# MISC_ANALOG_CTRL register map
Vendor: Texas Instruments
Peripheral module from a debugger description file (folder ucd3138064A).
Registers are 32-bit, access not given, no defined reset value unless marked. A register's access mark holds for its fields unless they carry their own. Offsets are as the file gives them; lines under a group give offsets from that group; [hi:lo] are bit positions; {n}, {i} and the like mark numbered series; 'fields as' and 'values as' point back to an identical list; <NAME> marks a mode.

## MISCANALOG
0x10 PKGID
  [1:0] PKG_ID rw — Package ID
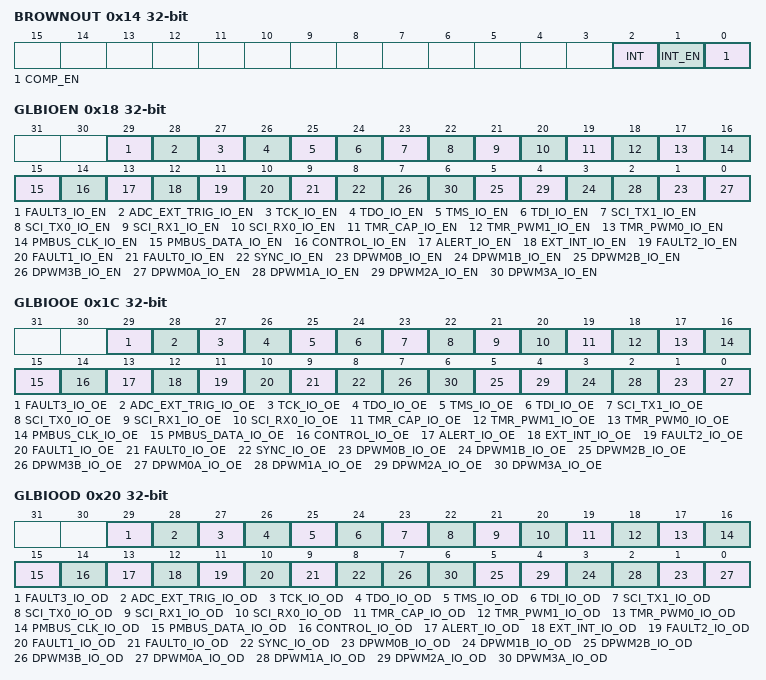
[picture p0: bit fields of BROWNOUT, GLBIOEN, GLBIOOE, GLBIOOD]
0x14 BROWNOUT
  [2] INT ro — Brownout Interrupt Latched Status
  [1] INT_EN rw — Brownout Interrupt Enable
  [0] COMP_EN rw — Brownout Enable
0x18 GLBIOEN
  [29] FAULT3_IO_EN rw — [pin=64]bit 29
  [28] ADC_EXT_TRIG_IO_EN rw — bit 28
  [27] TCK_IO_EN rw — bit 27
  [26] TDO_IO_EN rw — bit 26
  [25] TMS_IO_EN rw — bit 25
  [24] TDI_IO_EN rw — bit 24
  [23] SCI_TX1_IO_EN rw — [pin=64]bit 23
  [22] SCI_TX0_IO_EN rw — bit 22
  [21] SCI_RX1_IO_EN rw — [pin=64]bit 21
  [20] SCI_RX0_IO_EN rw — bit 20
  [19] TMR_CAP_IO_EN rw — bit 19
  [18] TMR_PWM1_IO_EN rw — bit 18
  [17] TMR_PWM0_IO_EN rw — bit 17
  [16] PMBUS_CLK_IO_EN rw — bit 16
  [15] PMBUS_DATA_IO_EN rw — bit 15
  [14] CONTROL_IO_EN rw — bit 14
  [13] ALERT_IO_EN rw — bit 13
  [12] EXT_INT_IO_EN rw — bit 12
  [11] FAULT2_IO_EN rw — bit 11
  [10] FAULT1_IO_EN rw — bit 10
  [9] FAULT0_IO_EN rw — bit 9
  [8] SYNC_IO_EN rw — bit 8
  [2n+1] DPWM{n}B_IO_EN rw (n=0..3) — bit {2n+1}
  [2n] DPWM{n}A_IO_EN rw (n=0..3) — bit {2n}
0x1C GLBIOOE
  [29] FAULT3_IO_OE rw — [pin=64]bit 29
  [28] ADC_EXT_TRIG_IO_OE rw — bit 28
  [27] TCK_IO_OE rw — bit 27
  [26] TDO_IO_OE rw — bit 26
  [25] TMS_IO_OE rw — bit 25
  [24] TDI_IO_OE rw — bit 24
  [23] SCI_TX1_IO_OE rw — [pin=64]bit 23
  [22] SCI_TX0_IO_OE rw — bit 22
  [21] SCI_RX1_IO_OE rw — [pin=64]bit 21
  [20] SCI_RX0_IO_OE rw — bit 20
  [19] TMR_CAP_IO_OE rw — bit 19
  [18] TMR_PWM1_IO_OE rw — bit 18
  [17] TMR_PWM0_IO_OE rw — bit 17
  [16] PMBUS_CLK_IO_OE rw — bit 16
  [15] PMBUS_DATA_IO_OE rw — bit 15
  [14] CONTROL_IO_OE rw — bit 14
  [13] ALERT_IO_OE rw — bit 13
  [12] EXT_INT_IO_OE rw — bit 12
  [11] FAULT2_IO_OE rw — bit 11
  [10] FAULT1_IO_OE rw — bit 10
  [9] FAULT0_IO_OE rw — bit 9
  [8] SYNC_IO_OE rw — bit 8
  [2n+1] DPWM{n}B_IO_OE rw (n=0..3) — bit {2n+1}
  [2n] DPWM{n}A_IO_OE rw (n=0..3) — bit {2n}
0x20 GLBIOOD
  [29] FAULT3_IO_OD rw — [pin=64]bit 29
  [28] ADC_EXT_TRIG_IO_OD rw — bit 28
  [27] TCK_IO_OD rw — bit 27
  [26] TDO_IO_OD rw — bit 26
  [25] TMS_IO_OD rw — bit 25
  [24] TDI_IO_OD rw — bit 24
  [23] SCI_TX1_IO_OD rw — [pin=64]bit 23
  [22] SCI_TX0_IO_OD rw — bit 22
  [21] SCI_RX1_IO_OD rw — [pin=64]bit 21
  [20] SCI_RX0_IO_OD rw — bit 20
  [19] TMR_CAP_IO_OD rw — bit 19
  [18] TMR_PWM1_IO_OD rw — bit 18
  [17] TMR_PWM0_IO_OD rw — bit 17
  [16] PMBUS_CLK_IO_OD rw — bit 16
  [15] PMBUS_DATA_IO_OD rw — bit 15
  [14] CONTROL_IO_OD rw — bit 14
  [13] ALERT_IO_OD rw — bit 13
  [12] EXT_INT_IO_OD rw — bit 12
  [11] FAULT2_IO_OD rw — bit 11
  [10] FAULT1_IO_OD rw — bit 10
  [9] FAULT0_IO_OD rw — bit 9
  [8] SYNC_IO_OD rw — bit 8
  [2n+1] DPWM{n}B_IO_OD rw (n=0..3) — bit {2n+1}
  [2n] DPWM{n}A_IO_OD rw (n=0..3) — bit {2n}
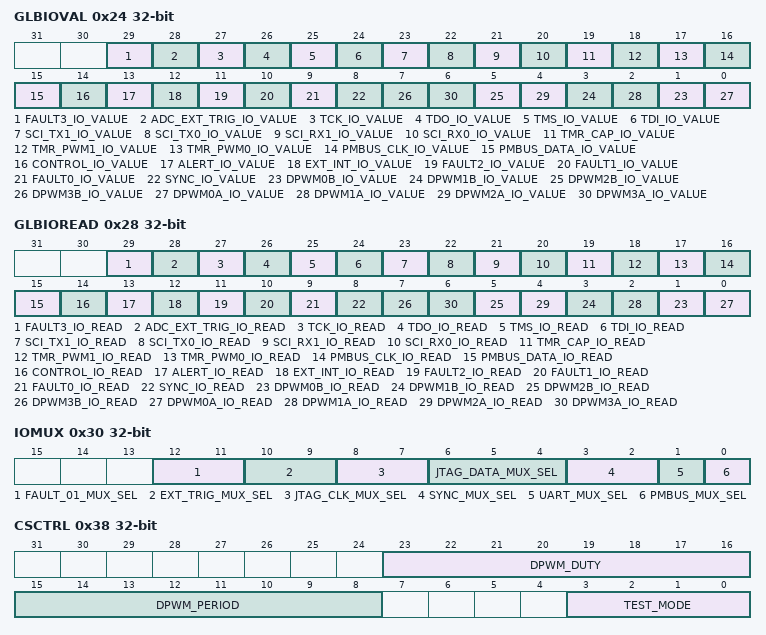
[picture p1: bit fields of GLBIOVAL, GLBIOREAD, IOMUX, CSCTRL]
0x24 GLBIOVAL
  [29] FAULT3_IO_VALUE rw — [pin=64]bit 29
  [28] ADC_EXT_TRIG_IO_VALUE rw — bit 28
  [27] TCK_IO_VALUE rw — bit 27
  [26] TDO_IO_VALUE rw — bit 26
  [25] TMS_IO_VALUE rw — bit 25
  [24] TDI_IO_VALUE rw — bit 24
  [23] SCI_TX1_IO_VALUE rw — [pin=64]bit 23
  [22] SCI_TX0_IO_VALUE rw — bit 22
  [21] SCI_RX1_IO_VALUE rw — [pin=64]bit 21
  [20] SCI_RX0_IO_VALUE rw — bit 20
  [19] TMR_CAP_IO_VALUE rw — bit 19
  [18] TMR_PWM1_IO_VALUE rw — [pin=64]bit 18
  [17] TMR_PWM0_IO_VALUE rw — bit 17
  [16] PMBUS_CLK_IO_VALUE rw — bit 16
  [15] PMBUS_DATA_IO_VALUE rw — bit 15
  [14] CONTROL_IO_VALUE rw — bit 14
  [13] ALERT_IO_VALUE rw — bit 13
  [12] EXT_INT_IO_VALUE rw — [pin=64]bit 12
  [11] FAULT2_IO_VALUE rw — bit 11
  [10] FAULT1_IO_VALUE rw — bit 10
  [9] FAULT0_IO_VALUE rw — bit 9
  [8] SYNC_IO_VALUE rw — bit 8
  [2n+1] DPWM{n}B_IO_VALUE rw (n=0..3) — bit {2n+1}
  [2n] DPWM{n}A_IO_VALUE rw (n=0..3) — bit {2n}
0x28 GLBIOREAD
  [29] FAULT3_IO_READ ro — [pin=64]bit 29
  [28] ADC_EXT_TRIG_IO_READ ro — bit 28
  [27] TCK_IO_READ ro — bit 27
  [26] TDO_IO_READ ro — bit 26
  [25] TMS_IO_READ ro — bit 25
  [24] TDI_IO_READ ro — bit 24
  [23] SCI_TX1_IO_READ ro — [pin=64]bit 23
  [22] SCI_TX0_IO_READ ro — bit 22
  [21] SCI_RX1_IO_READ ro — [pin=64]bit 21
  [20] SCI_RX0_IO_READ ro — bit 20
  [19] TMR_CAP_IO_READ ro — bit 19
  [18] TMR_PWM1_IO_READ ro — [pin=64]bit 18
  [17] TMR_PWM0_IO_READ ro — bit 17
  [16] PMBUS_CLK_IO_READ ro — bit 16
  [15] PMBUS_DATA_IO_READ ro — bit 15
  [14] CONTROL_IO_READ ro — bit 14
  [13] ALERT_IO_READ ro — bit 13
  [12] EXT_INT_IO_READ ro — [pin=64]bit 12
  [11] FAULT2_IO_READ ro — bit 11
  [10] FAULT1_IO_READ ro — bit 10
  [9] FAULT0_IO_READ ro — bit 9
  [8] SYNC_IO_READ ro — bit 8
  [2n+1] DPWM{n}B_IO_READ ro (n=0..3) — bit {2n+1}
  [2n] DPWM{n}A_IO_READ ro (n=0..3) — bit {2n}
0x30 IOMUX
  [12:11] FAULT_01_MUX_SEL rw — FAULT 0/1 Pins Mux Control
  [10:9] EXT_TRIG_MUX_SEL rw — EXT TRIG Pins Mux Control
  [8:7] JTAG_CLK_MUX_SEL rw — JTAG Data Pins Mux Control
  [6:4] JTAG_DATA_MUX_SEL rw — JTAG Data Pins Mux Control
  [3:2] SYNC_MUX_SEL rw — SYNC Pins Mux Control
  [1] UART_MUX_SEL rw — UART Pins Mux Control
  [0] PMBUS_MUX_SEL rw — PMBus Pins Mux Control
0x38 CSCTRL
  [23:16] DPWM_DUTY rw — DPWM Duty/Pulse Width for Cur Share
  [15:8] DPWM_PERIOD rw — DPWM Period for Current Share
  [3:0] TEST_MODE rw — Current Sharing Test Mode
0x3C TEMPREF
  [11:0] TEMP_REF rw — Temperature Reference
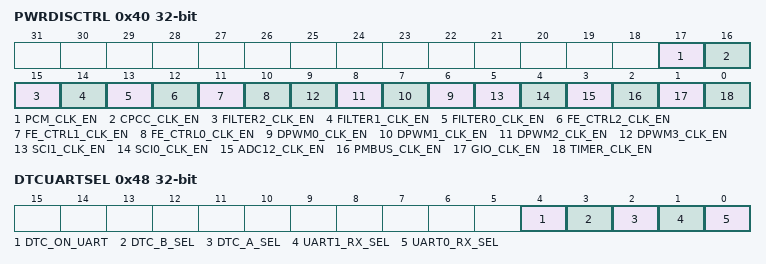
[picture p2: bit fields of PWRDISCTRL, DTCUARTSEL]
0x40 PWRDISCTRL
  [17] PCM_CLK_EN rw — Peak Current Mode Clock Enable
  [16] CPCC_CLK_EN rw — Constant Power/Constant Current Clock Enable
  [15] FILTER2_CLK_EN rw — Filter 2 Clock Enable
  [14] FILTER1_CLK_EN rw — Filter 1 Clock Enable
  [13] FILTER0_CLK_EN rw — Filter 0 Clock Enable
  [12] FE_CTRL2_CLK_EN rw — Front End Control 2 Clock Enable
  [11] FE_CTRL1_CLK_EN rw — Front End Control 2 Clock Enable
  [10] FE_CTRL0_CLK_EN rw — Front End Control 2 Clock Enable
  [n+6] DPWM{n}_CLK_EN rw (n=0..3) — DPWM4 Clock Enable
  [5] SCI1_CLK_EN rw — SCI1 Clock Enable
  [4] SCI0_CLK_EN rw — SCI0 Clock Enable
  [3] ADC12_CLK_EN rw — ADC12 Control Clock Enable
  [2] PMBUS_CLK_EN rw — PMBus I/F Clock Enable
  [1] GIO_CLK_EN rw — GIO Clock Enable
  [0] TIMER_CLK_EN rw — Timer Clock Enable
0x48 DTCUARTSEL
  [4] DTC_ON_UART rw — DTC via UART RX/TX 1
  [3] DTC_B_SEL rw — DTC Phase B Input Control
  [2] DTC_A_SEL rw — DTC Phase A Input Control
  [1] UART1_RX_SEL rw — [pin=64]UART1 Receive Pin Control
  [0] UART0_RX_SEL rw — UART0 Receive Pin Control
